# CH32V407 register map
Vendor: WCH Ltd.; File version: 1.0
Registers are 32-bit, read-write, reset 0x0 unless marked. A register's access mark holds for its fields unless they carry their own. Offsets are from the block's base; [hi:lo] are bit positions; {n}, {i} and the like mark numbered series.

## RCC — Reset and clock control
Base 0x40021000
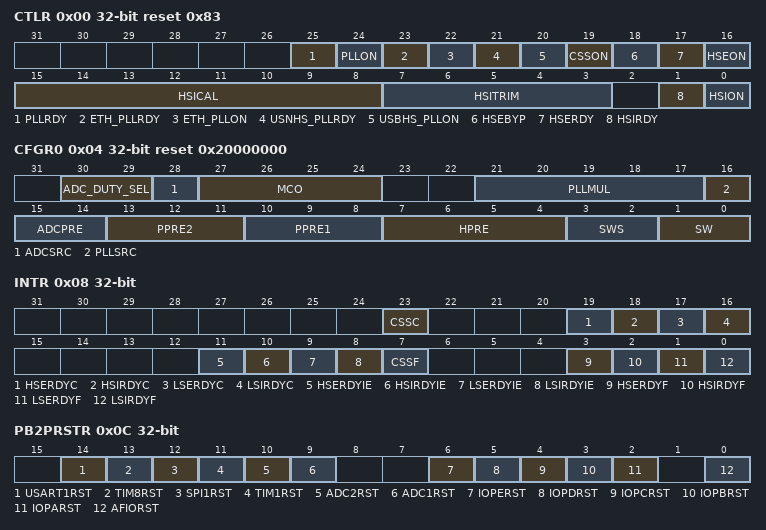
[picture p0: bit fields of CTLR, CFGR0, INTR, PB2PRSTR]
0x00 CTLR access per field reset 0x83 — Clock control register
  [25] PLLRDY ro — PLL clock ready flag
  [24] PLLON rw — PLL clock enable
  [23] ETH_PLLRDY ro — ETH PLL clock ready flag
  [22] ETH_PLLON rw — ETH PLL enable
  [21] USNHS_PLLRDY ro — USNHS PLL clock ready flag
  [20] USBHS_PLLON rw — USBHS PLL enable
  [19] CSSON rw — Clock Security System enable
  [18] HSEBYP rw — External High Speed clock Bypass
  [17] HSERDY ro — External High Speed clock ready flag
  [16] HSEON rw — External High Speed clock enable
  [15:8] HSICAL ro — Internal High Speed clock Calibration
  [7:3] HSITRIM rw — Internal High Speed clock trimming
  [1] HSIRDY ro — Internal High Speed clock ready flag
  [0] HSION rw — Internal High Speed clock enable
0x04 CFGR0 access per field reset 0x20000000 — Clock configuration register (RCC_CFGR0)
  [30:29] ADC_DUTY_SEL rw — ADC clock duty cycle selection
  [28] ADCSRC ro — ADC input clock source selection
  [27:24] MCO rw — Microcontroller clock output
  [21:17] PLLMUL rw — PLL clock multiplication factor
  [16] PLLSRC rw — PLL intput clock source selection
  [15:14] ADCPRE rw — ADC prescaler
  [13:11] PPRE2 rw — PB High speed prescaler (PB2)
  [10:8] PPRE1 rw — PB Low speed prescaler (PB1)
  [7:4] HPRE rw — HB prescaler
  [3:2] SWS ro — System Clock Switch Status
  [1:0] SW rw — System clock Switch
0x08 INTR access per field — Clock interrupt register (RCC_INTR)
  [23] CSSC wo — Clock security system interrupt clear
  [19] HSERDYC wo — HSE Ready Interrupt Clear
  [18] HSIRDYC wo — HSI Ready Interrupt Clear
  [17] LSERDYC wo — LSE Ready Interrupt Clear
  [16] LSIRDYC wo — LSI Ready Interrupt Clear
  [11] HSERDYIE rw — HSE Ready Interrupt Enable
  [10] HSIRDYIE rw — HSI Ready Interrupt Enable
  [9] LSERDYIE rw — LSE Ready Interrupt Enable
  [8] LSIRDYIE rw — LSI Ready Interrupt Enable
  [7] CSSF ro — Clock Security System Interrupt flag
  [3] HSERDYF ro — HSE Ready Interrupt flag
  [2] HSIRDYF ro — HSI Ready Interrupt flag
  [1] LSERDYF ro — LSE Ready Interrupt flag
  [0] LSIRDYF ro — LSI Ready Interrupt flag
0x0C PB2PRSTR — PB2 peripheral reset register (RCC_PB2PRSTR)
  [14] USART1RST — USART1 reset
  [13] TIM8RST — TIM8 timer reset
  [12] SPI1RST — SPI 1 reset
  [11] TIM1RST — TIM1 timer reset
  [10] ADC2RST — ADC 2 interface reset
  [9] ADC1RST — ADC 1 interface reset
  [6] IOPERST — IO port E reset
  [5] IOPDRST — IO port D reset
  [4] IOPCRST — IO port C reset
  [3] IOPBRST — IO port B reset
  [2] IOPARST — IO port A reset
  [0] AFIORST — Alternate function I/O reset
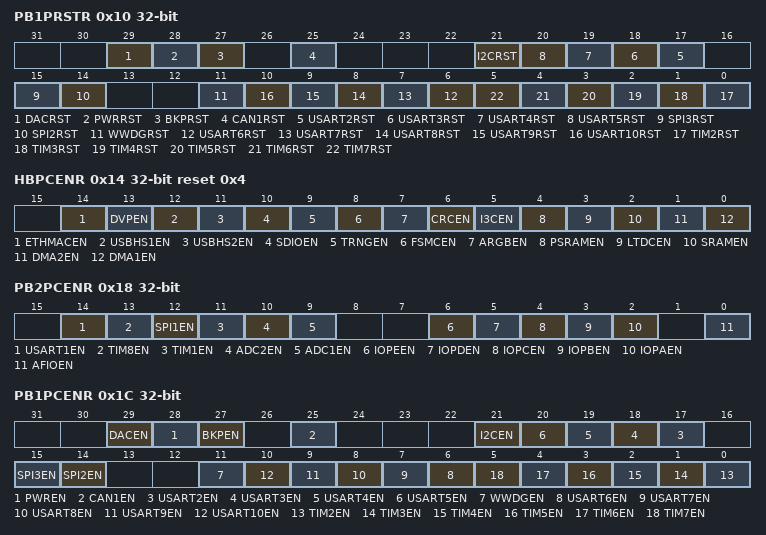
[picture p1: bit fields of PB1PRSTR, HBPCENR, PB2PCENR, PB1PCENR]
0x10 PB1PRSTR — PB1 peripheral reset register (RCC_PB1PRSTR)
  [29] DACRST — DAC interface reset
  [28] PWRRST — Power interface reset
  [27] BKPRST — Backup interface reset
  [25] CAN1RST — CAN1 reset
  [21] I2CRST — I2C reset
  [n+15] USART{n}RST (n=2..5) — USART {n} reset
  [15] SPI3RST — SPI3 reset
  [14] SPI2RST — SPI2 reset
  [11] WWDGRST — Window watchdog reset
  [n] USART{n}RST (n=6..10) — USART {n} reset
  [n-2] TIM{n}RST (n=2..7) — Timer {n} reset
0x14 HBPCENR reset 0x4 — HB Peripheral Clock enable register (RCC_HBPCENR)
  [14] ETHMACEN — Ethernet MAC clock enable
  [13] DVPEN — DVP clock enable
  [12] USBHS1EN — USBHS1_EN clock enable
  [11] USBHS2EN — USBHS2 clock enable
  [10] SDIOEN — SDIO clock enable
  [9] TRNGEN — TRNG clock enable
  [8] FSMCEN — FSMC clock enable
  [7] ARGBEN — ARGB clock enable
  [6] CRCEN — CRC clock enable
  [5] I3CEN — I3C clock enable
  [4] PSRAMEN — PSRAM clock enable
  [3] LTDCEN — LTDC clock enable
  [2] SRAMEN — SRAM interface clock enable
  [1] DMA2EN — DMA2 clock enable
  [0] DMA1EN — DMA clock enable
0x18 PB2PCENR — PB2 peripheral clock enable register (RCC_PB2PCENR)
  [14] USART1EN — USART1 clock enable
  [13] TIM8EN — TIM8 Timer clock enable
  [12] SPI1EN — SPI 1 clock enable
  [11] TIM1EN — TIM1 Timer clock enable
  [10] ADC2EN — ADC 2 interface clock enable
  [9] ADC1EN — ADC1 interface clock enable
  [6] IOPEEN — I/O port E clock enable
  [5] IOPDEN — I/O port D clock enable
  [4] IOPCEN — I/O port C clock enable
  [3] IOPBEN — I/O port B clock enable
  [2] IOPAEN — I/O port A clock enable
  [0] AFIOEN — Alternate function I/O clock enable
0x1C PB1PCENR — PB1 peripheral clock enable register (RCC_PB1PCENR)
  [29] DACEN — DAC interface clock enable
  [28] PWREN — Power interface clock enable
  [27] BKPEN — Backup interface clock enable
  [25] CAN1EN — CAN1 clock enable
  [21] I2CEN — I2C 1 clock enable
  [n+15] USART{n}EN (n=2..5) — USART {n} clock enable
  [15] SPI3EN — SPI 3 clock enable
  [14] SPI2EN — SPI 2 clock enable
  [11] WWDGEN — Window watchdog clock enable
  [n] USART{n}EN (n=6..10) — USART {n} clock enable
  [n-2] TIM{n}EN (n=2..7) — Timer {n} clock enable
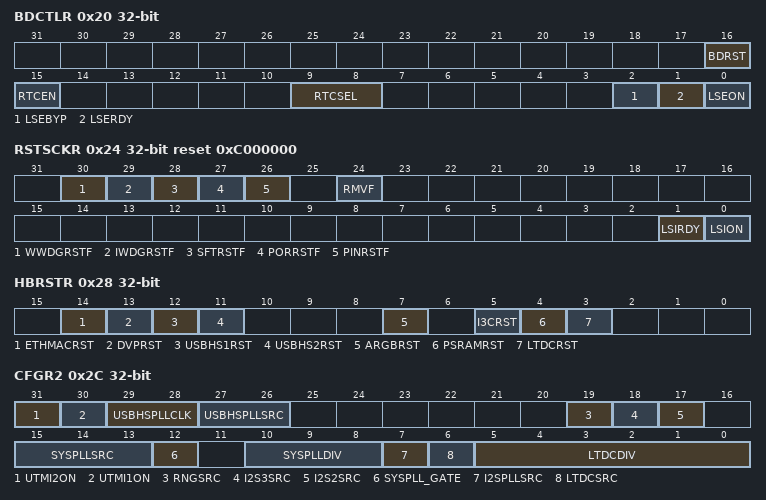
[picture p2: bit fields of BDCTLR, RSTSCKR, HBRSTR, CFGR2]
0x20 BDCTLR access per field — Backup domain control register (RCC_BDCTLR)
  [16] BDRST rw — Backup domain software reset
  [15] RTCEN rw — RTC clock enable
  [9:8] RTCSEL rw — RTC clock source selection
  [2] LSEBYP rw — External Low Speed oscillator bypass
  [1] LSERDY ro — External Low Speed oscillator ready
  [0] LSEON rw — External Low Speed oscillator enable
0x24 RSTSCKR access per field reset 0xC000000 — Control/status register (RCC_RSTSCKR)
  [30] WWDGRSTF ro — Window watchdog reset flag
  [29] IWDGRSTF ro — Independent watchdog reset flag
  [28] SFTRSTF ro — Software reset flag
  [27] PORRSTF ro — POR/PDR reset flag
  [26] PINRSTF ro — PIN reset flag
  [24] RMVF ro — Remove reset flag
  [1] LSIRDY ro — Internal low speed oscillator ready
  [0] LSION rw — Internal low speed oscillator enable
0x28 HBRSTR — HB reset register (RCC_PHBRSTR)
  [14] ETHMACRST — Ethernet MAC reset
  [13] DVPRST — DVP reset
  [12] USBHS1RST — USBHS1 reset
  [11] USBHS2RST — USBHS2 reset
  [7] ARGBRST — ARGB reset
  [5] I3CRST — I3C reset
  [4] PSRAMRST — PSRAM reset
  [3] LTDCRST — LTDC reset
0x2C CFGR2 — Clock configuration register2 (RCC_CFGR2)
  [31] UTMI2ON — UTMI2 Clock gate enable
  [30] UTMI1ON — UTMI1 Clock gate enable
  [29:28] USBHSPLLCLK — USBHS Peference Clock source
  [27:26] USBHSPLLSRC — USBHS Multiplication Factor clock source
  [19] RNGSRC — TRNG clock source
  [18] I2S3SRC — I2S3 clock source
  [17] I2S2SRC — I2S2 clock source
  [15:13] SYSPLLSRC — SYSPLL clock source selection
  [12] SYSPLL_GATE — SYSPLL gate enable
  [10:8] SYSPLLDIV — PLL division factor
  [7] I2SPLLSRC — I2S PLL clock source selection
  [6] LTDCSRC — LTDC clock source selection
  [5:0] LTDCDIV — LTDC division factor
0x30 CFGR3 — Clock configuration register3 (RCC_CFGR3)
  [4:0] ADC_CLKDIV — Clock division configuration when the ADC clock source selects USBHS_PLL
